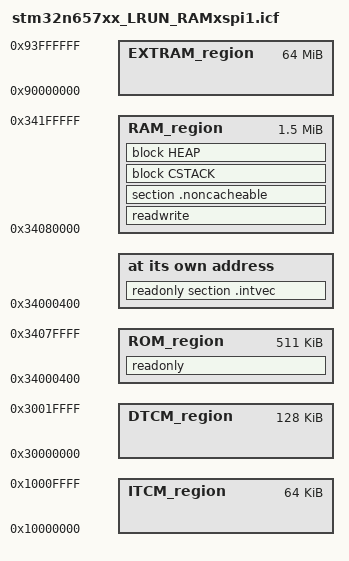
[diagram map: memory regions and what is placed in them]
/*###ICF### Section handled by ICF editor, don't touch! ****/
/*-Editor annotation file-*/
/* IcfEditorFile="$TOOLKIT_DIR$\config\ide\IcfEditor\cortex_v1_0.xml" */
/*-Specials-*/
define symbol __ICFEDIT_intvec_start__ = 0x34000400;
/*-Memory Regions-*/
define symbol __ICFEDIT_region_ROM_start__ = 0x34000400;
define symbol __ICFEDIT_region_ROM_end__   = 0x3407FFFF;
define symbol __ICFEDIT_region_RAM_start__ = 0x34080000;
define symbol __ICFEDIT_region_RAM_end__   = 0x341FFFFF;
/*-Sizes-*/
define symbol __ICFEDIT_size_cstack__ = 0x800;
define symbol __ICFEDIT_size_heap__   = 0x200;
/**** End of ICF editor section. ###ICF###*/

define symbol __region_ITCM_start__  = 0x10000000;
define symbol __region_ITCM_end__    = 0x1000FFFF;
define symbol __region_DTCM_start__  = 0x30000000;
define symbol __region_DTCM_end__    = 0x3001FFFF;
define symbol __region_EXTRAM_start__ = 0x90000000;
define symbol __region_EXTRAM_end__   = 0x93FFFFFF;

export symbol __region_EXTRAM_start__;
export symbol __region_EXTRAM_end__;

define memory mem with size = 4G;
define region ROM_region      = mem:[from __ICFEDIT_region_ROM_start__ to __ICFEDIT_region_ROM_end__];
define region RAM_region      = mem:[from __ICFEDIT_region_RAM_start__ to __ICFEDIT_region_RAM_end__];
define region EXTRAM_region   = mem:[from __region_EXTRAM_start__ to __region_EXTRAM_end__];
define region ITCM_region     = mem:[from __region_ITCM_start__ to __region_ITCM_end__];
define region DTCM_region     = mem:[from __region_DTCM_start__ to __region_DTCM_end__];

define block CSTACK    with alignment = 8, size = __ICFEDIT_size_cstack__   { };
define block HEAP      with alignment = 8, size = __ICFEDIT_size_heap__     { };

initialize by copy { readwrite };
do not initialize  { section .noinit };

place at address mem:__ICFEDIT_intvec_start__ { readonly section .intvec };

place in ROM_region   { readonly };
place in RAM_region   { readwrite, section .noncacheable,
                        block CSTACK, block HEAP };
